AUTOSAR XML (schema 314)
package /ComponentType
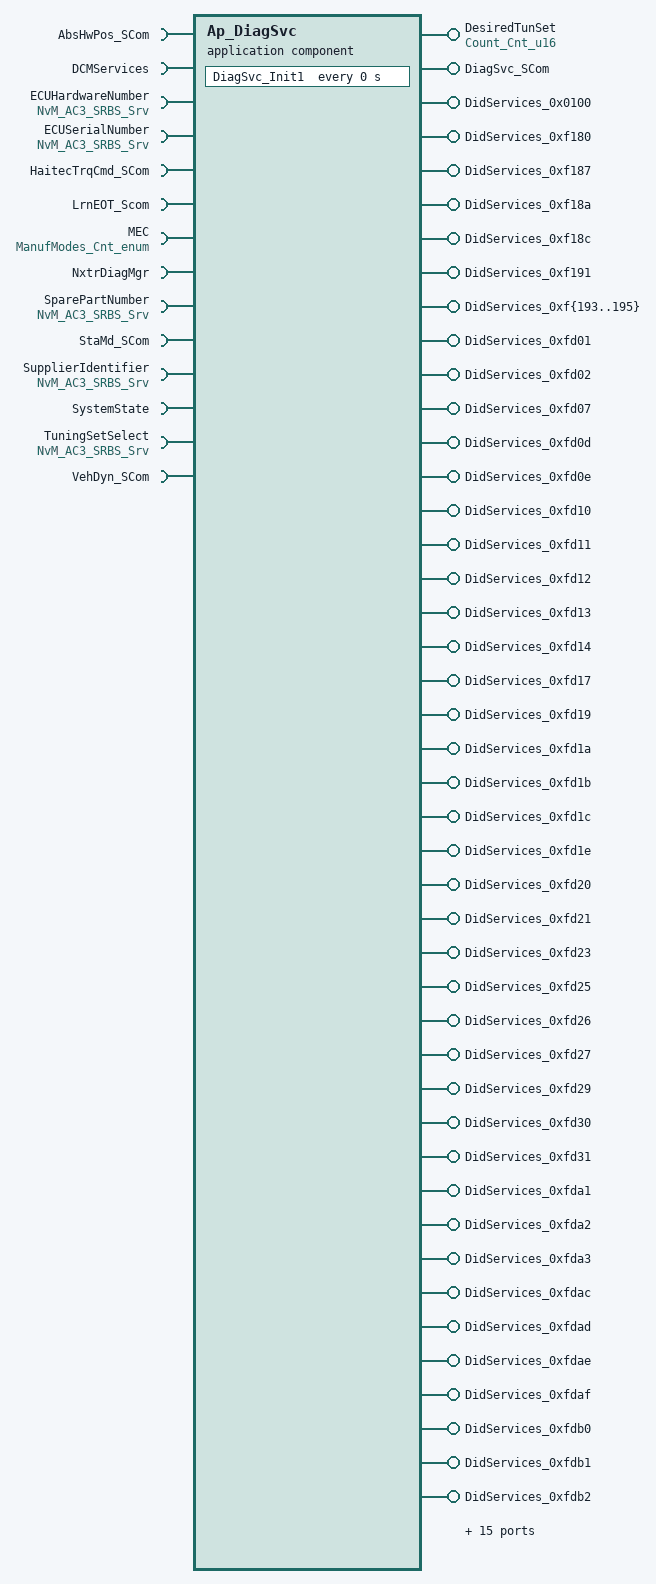
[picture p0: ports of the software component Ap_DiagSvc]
  application software component type Ap_DiagSvc
    63 x provide port:
      DesiredTunSet: unqueued-sender-com-spec{data-element=Cnt_u16, can-invalidate=false, init-value=D_ZERO_CNT_U16}, provided-interface=Count_Cnt_u16
      DiagSvc_SCom: provided-com-specs=[{operation=GetTuningSet, queue-length=1}, {operation=SetTuningSet, queue-length=1}], provided-interface=DiagSvc_SCom
      DidServices_0x0100: provided-interface=DidServices_0x0100
        provided-com-specs:
          operation=ConditionCheckRead, queue-length=1
          operation=ConditionCheckWrite, queue-length=1
          operation=ReadData, queue-length=1
          operation=WriteData, queue-length=1
      DidServices_0xf180: provided-com-specs=[{operation=ConditionCheckRead, queue-length=1}, {operation=ReadData, queue-length=1}], provided-interface=DidServices_0xf180
      DidServices_0xf187: provided-interface=DidServices_0xf187
        provided-com-specs:
          operation=ConditionCheckRead, queue-length=1
          operation=ConditionCheckWrite, queue-length=1
          operation=ReadData, queue-length=1
          operation=WriteData, queue-length=1
      DidServices_0xf18a: provided-interface=DidServices_0xf18a
        provided-com-specs:
          operation=ConditionCheckRead, queue-length=1
          operation=ConditionCheckWrite, queue-length=1
          operation=ReadData, queue-length=1
          operation=WriteData, queue-length=1
      DidServices_0xf18c: provided-com-specs=[{operation=ConditionCheckRead, queue-length=1}, {operation=ReadData, queue-length=1}], provided-interface=DidServices_0xf18c
      DidServices_0xf191: provided-com-specs=[{operation=ConditionCheckRead, queue-length=1}, {operation=ReadData, queue-length=1}], provided-interface=DidServices_0xf191
      DidServices_0xf{193..195}: provided-com-specs=[{operation=ConditionCheckRead, queue-length=1}, {operation=ReadData, queue-length=1}], provided-interface=DidServices_0xf{193..195}
      DidServices_0xfd01: provided-com-specs=[{operation=ConditionCheckRead, queue-length=1}, {operation=ReadData, queue-length=1}], provided-interface=DidServices_0xfd01
      DidServices_0xfd02: provided-interface=DidServices_0xfd02
        provided-com-specs:
          operation=ConditionCheckRead, queue-length=1
          operation=ConditionCheckWrite, queue-length=1
          operation=ReadData, queue-length=1
          operation=WriteData, queue-length=1
      DidServices_0xfd07: provided-interface=DidServices_0xfd07
        provided-com-specs:
          operation=ConditionCheckRead, queue-length=1
          operation=ConditionCheckWrite, queue-length=1
          operation=ReadData, queue-length=1
          operation=WriteData, queue-length=1
      DidServices_0xfd0d: provided-interface=DidServices_0xfd0d
        provided-com-specs:
          operation=ConditionCheckRead, queue-length=1
          operation=ReadData, queue-length=1
          operation=ReturnControlToECU, queue-length=1
          operation=ShortTermAdjustment, queue-length=1
      DidServices_0xfd0e: provided-com-specs=[{operation=ConditionCheckRead, queue-length=1}, {operation=ReadData, queue-length=1}], provided-interface=DidServices_0xfd0e
      DidServices_0xfd10: provided-com-specs=[{operation=ConditionCheckRead, queue-length=1}, {operation=ReadData, queue-length=1}], provided-interface=DidServices_0xfd10
      DidServices_0xfd11: provided-interface=DidServices_0xfd11
        provided-com-specs:
          operation=ConditionCheckRead, queue-length=1
          operation=ReadData, queue-length=1
          operation=ReturnControlToECU, queue-length=1
          operation=ShortTermAdjustment, queue-length=1
      DidServices_0xfd12: provided-interface=DidServices_0xfd12
        provided-com-specs:
          operation=ConditionCheckRead, queue-length=1
          operation=ConditionCheckWrite, queue-length=1
          operation=ReadData, queue-length=1
          operation=WriteData, queue-length=1
      DidServices_0xfd13: provided-com-specs=[{operation=ConditionCheckRead, queue-length=1}, {operation=ReadData, queue-length=1}], provided-interface=DidServices_0xfd13
      DidServices_0xfd14: provided-com-specs=[{operation=ConditionCheckRead, queue-length=1}, {operation=ReadData, queue-length=1}], provided-interface=DidServices_0xfd14
      DidServices_0xfd17: provided-com-specs=[{operation=ConditionCheckRead, queue-length=1}, {operation=ReadData, queue-length=1}], provided-interface=DidServices_0xfd17
      DidServices_0xfd19: provided-interface=DidServices_0xfd19
        provided-com-specs:
          operation=ConditionCheckRead, queue-length=1
          operation=ConditionCheckWrite, queue-length=1
          operation=ReadData, queue-length=1
          operation=WriteData, queue-length=1
      DidServices_0xfd1a: provided-com-specs=[{operation=ConditionCheckRead, queue-length=1}, {operation=ReadData, queue-length=1}], provided-interface=DidServices_0xfd1a
      DidServices_0xfd1b: provided-interface=DidServices_0xfd1b
        provided-com-specs:
          operation=ConditionCheckRead, queue-length=1
          operation=ConditionCheckWrite, queue-length=1
          operation=ReadData, queue-length=1
          operation=WriteData, queue-length=1
      DidServices_0xfd1c: provided-com-specs=[{operation=ConditionCheckRead, queue-length=1}, {operation=ReadData, queue-length=1}], provided-interface=DidServices_0xfd1c
      DidServices_0xfd1e: provided-interface=DidServices_0xfd1e
        provided-com-specs:
          operation=ConditionCheckRead, queue-length=1
          operation=ConditionCheckWrite, queue-length=1
          operation=ReadData, queue-length=1
          operation=WriteData, queue-length=1
      DidServices_0xfd20: provided-com-specs=[{operation=ConditionCheckRead, queue-length=1}, {operation=ReadData, queue-length=1}], provided-interface=DidServices_0xfd20
      DidServices_0xfd21: provided-interface=DidServices_0xfd21
        provided-com-specs:
          operation=ConditionCheckRead, queue-length=1
          operation=ConditionCheckWrite, queue-length=1
          operation=ReadData, queue-length=1
          operation=WriteData, queue-length=1
      DidServices_0xfd23: provided-interface=DidServices_0xfd23
        provided-com-specs:
          operation=ConditionCheckRead, queue-length=1
          operation=ConditionCheckWrite, queue-length=1
          operation=ReadData, queue-length=1
          operation=WriteData, queue-length=1
      DidServices_0xfd25: provided-interface=DidServices_0xfd25
        provided-com-specs:
          operation=ConditionCheckRead, queue-length=1
          operation=ConditionCheckWrite, queue-length=1
          operation=ReadData, queue-length=1
          operation=WriteData, queue-length=1
      DidServices_0xfd26: provided-interface=DidServices_0xfd26
        provided-com-specs:
          operation=ConditionCheckRead, queue-length=1
          operation=ConditionCheckWrite, queue-length=1
          operation=ReadData, queue-length=1
          operation=WriteData, queue-length=1
      DidServices_0xfd27: provided-interface=DidServices_0xfd27
        provided-com-specs:
          operation=ConditionCheckRead, queue-length=1
          operation=ConditionCheckWrite, queue-length=1
          operation=ReadData, queue-length=1
          operation=WriteData, queue-length=1
      DidServices_0xfd29: provided-interface=DidServices_0xfd29
        provided-com-specs:
          operation=ConditionCheckRead, queue-length=1
          operation=ConditionCheckWrite, queue-length=1
          operation=ReadData, queue-length=1
          operation=WriteData, queue-length=1
      DidServices_0xfd30: provided-interface=DidServices_0xfd30
        provided-com-specs:
          operation=ConditionCheckRead, queue-length=1
          operation=ConditionCheckWrite, queue-length=1
          operation=ReadData, queue-length=1
          operation=WriteData, queue-length=1
      DidServices_0xfd31: provided-com-specs=[{operation=ConditionCheckRead, queue-length=1}, {operation=ReadData, queue-length=1}], provided-interface=DidServices_0xfd31
      DidServices_0xfda1: provided-interface=DidServices_0xfda1
        provided-com-specs:
          operation=ConditionCheckRead, queue-length=1
          operation=ConditionCheckWrite, queue-length=1
          operation=ReadData, queue-length=1
          operation=WriteData, queue-length=1
      DidServices_0xfda2: provided-interface=DidServices_0xfda2
        provided-com-specs:
          operation=ConditionCheckRead, queue-length=1
          operation=ConditionCheckWrite, queue-length=1
          operation=ReadData, queue-length=1
          operation=WriteData, queue-length=1
      DidServices_0xfda3: provided-interface=DidServices_0xfda3
        provided-com-specs:
          operation=ConditionCheckRead, queue-length=1
          operation=ConditionCheckWrite, queue-length=1
          operation=ReadData, queue-length=1
          operation=WriteData, queue-length=1
      DidServices_0xfdac: provided-interface=DidServices_0xfdac
        provided-com-specs:
          operation=ConditionCheckRead, queue-length=1
          operation=ConditionCheckWrite, queue-length=1
          operation=ReadData, queue-length=1
          operation=WriteData, queue-length=1
      DidServices_0xfdad: provided-com-specs=[{operation=ConditionCheckRead, queue-length=1}, {operation=ReadData, queue-length=1}], provided-interface=DidServices_0xfdad
      DidServices_0xfdae: provided-interface=DidServices_0xfdae
        provided-com-specs:
          operation=ConditionCheckRead, queue-length=1
          operation=ConditionCheckWrite, queue-length=1
          operation=ReadData, queue-length=1
          operation=WriteData, queue-length=1
      DidServices_0xfdaf: provided-com-specs=[{operation=ConditionCheckRead, queue-length=1}, {operation=ReadData, queue-length=1}], provided-interface=DidServices_0xfdaf
      DidServices_0xfdb0: provided-interface=DidServices_0xfdb0
        provided-com-specs:
          operation=ConditionCheckRead, queue-length=1
          operation=ConditionCheckWrite, queue-length=1
          operation=ReadData, queue-length=1
          operation=WriteData, queue-length=1
      DidServices_0xfdb1: provided-interface=DidServices_0xfdb1
        provided-com-specs:
          operation=ConditionCheckRead, queue-length=1
          operation=ConditionCheckWrite, queue-length=1
          operation=ReadData, queue-length=1
          operation=WriteData, queue-length=1
      DidServices_0xfdb2: provided-interface=DidServices_0xfdb2
        provided-com-specs:
          operation=ConditionCheckRead, queue-length=1
          operation=ConditionCheckWrite, queue-length=1
          operation=ReadData, queue-length=1
          operation=WriteData, queue-length=1
      DidServices_0xfdb3: provided-interface=DidServices_0xfdb3
        provided-com-specs:
          operation=ConditionCheckRead, queue-length=1
          operation=ConditionCheckWrite, queue-length=1
          operation=ReadData, queue-length=1
          operation=WriteData, queue-length=1
      DidServices_0xfdb4: provided-interface=DidServices_0xfdb4
        provided-com-specs:
          operation=ConditionCheckRead, queue-length=1
          operation=ConditionCheckWrite, queue-length=1
          operation=ReadData, queue-length=1
          operation=WriteData, queue-length=1
      DidServices_0xfdb5: provided-interface=DidServices_0xfdb5
        provided-com-specs:
          operation=ConditionCheckRead, queue-length=1
          operation=ConditionCheckWrite, queue-length=1
          operation=ReadData, queue-length=1
          operation=WriteData, queue-length=1
      DidServices_0xfdb6: provided-interface=DidServices_0xfdb6
        provided-com-specs:
          operation=ConditionCheckRead, queue-length=1
          operation=ConditionCheckWrite, queue-length=1
          operation=ReadData, queue-length=1
          operation=WriteData, queue-length=1
      DidServices_0xfdb7: provided-interface=DidServices_0xfdb7
        provided-com-specs:
          operation=ConditionCheckRead, queue-length=1
          operation=ConditionCheckWrite, queue-length=1
          operation=ReadData, queue-length=1
          operation=WriteData, queue-length=1
      DidServices_0xfe00: provided-interface=DidServices_0xfe00
        provided-com-specs:
          operation=ConditionCheckRead, queue-length=1
          operation=ReadData, queue-length=1
          operation=ReturnControlToECU, queue-length=1
          operation=ShortTermAdjustment, queue-length=1
      RoutineServices_0xf000: server-com-spec{operation=Start, queue-length=1}, provided-interface=RoutineServices_0xf000
      RoutineServices_0xf001: server-com-spec{operation=Start, queue-length=1}, provided-interface=RoutineServices_0xf001
      RoutineServices_0xf{003..005}: server-com-spec{operation=Start, queue-length=1}, provided-interface=RoutineServices_0xf{003..005}
      RoutineServices_0xf008: server-com-spec{operation=Start, queue-length=1}, provided-interface=RoutineServices_0xf008
      RoutineServices_0xf009: provided-interface=RoutineServices_0xf009
        provided-com-specs:
          operation=RequestResults, queue-length=1
          operation=Start, queue-length=1
          operation=Stop, queue-length=1
      RoutineServices_0xf0ff: server-com-spec{operation=Start, queue-length=1}, provided-interface=RoutineServices_0xf0ff
      RoutineServices_0xfee0: server-com-spec{operation=Start, queue-length=1}, provided-interface=RoutineServices_0xfee0
      SecurityAccess_1: provided-com-specs=[{operation=CompareKey, queue-length=1}, {operation=GetSeed, queue-length=1}], provided-interface=SecurityAccess_1
      SessionControl: provided-interface=SessionControl
        provided-com-specs:
          operation=ChangeIndication, queue-length=1
          operation=ConfirmationRespPending, queue-length=1
          operation=GetSesChgPermission, queue-length=1
    14 x require port:
      AbsHwPos_SCom: required-com-specs=[CustClrTrim, CustSetTrim, NxtClearTrim, NxtSetTrim], required-interface=AbsHwPos_SCom
      DCMServices: required-com-specs=[GetSecurityLevel, GetSesCtrlType], required-interface=DCMServices
      ECUHardwareNumber: required-com-specs=[EraseBlock, GetErrorStatus, InvalidateNvBlock, ReadBlock, SetRamBlockStatus, WriteBlock], required-interface=NvM_AC3_SRBS_Srv
      ECUSerialNumber: required-com-specs=[EraseBlock, GetErrorStatus, InvalidateNvBlock, ReadBlock, SetRamBlockStatus, WriteBlock], required-interface=NvM_AC3_SRBS_Srv
      HaitecTrqCmd_SCom: required-com-specs=[StartCtrl, StopCtrl], required-interface=HaitecTrqCmd_SCom
      LrnEOT_Scom: client-com-spec=ResetEOT, required-interface=LrnEOT_Scom
      MEC: unqueued-receiver-com-spec{data-element=Cnt_enum, init-value=D_MANUFMODEINIT_CNT_ENUM}, required-interface=ManufModes_Cnt_enum
      NxtrDiagMgr: required-com-specs=[GetNTCActive, GetNTCFailed, GetNTCStatus, SetNTCStatus], required-interface=NxtrDiagMgr
      SparePartNumber: required-com-specs=[EraseBlock, GetErrorStatus, InvalidateNvBlock, ReadBlock, SetRamBlockStatus, WriteBlock], required-interface=NvM_AC3_SRBS_Srv
      StaMd_SCom: required-com-specs=[EcuReset, FBLTransitionReq], required-interface=StaMd_SCom
      SupplierIdentifier: required-com-specs=[EraseBlock, GetErrorStatus, InvalidateNvBlock, ReadBlock, SetRamBlockStatus, WriteBlock], required-interface=NvM_AC3_SRBS_Srv
      SystemState: required-interface=SystemState
      TuningSetSelect: required-com-specs=[EraseBlock, GetErrorStatus, InvalidateNvBlock, ReadBlock, SetRamBlockStatus, WriteBlock], required-interface=NvM_AC3_SRBS_Srv
      VehDyn_SCom: client-com-spec=ResetCenter, required-interface=VehDyn_SCom
  internal behavior Ap_DiagSvc_InternalBehavior: component=Ap_DiagSvc
    timing event DiagSvc_Init1_InitEvent: start-on-event=DiagSvc_Init1, period=0
    182 x operation invoked event:
      OIT_DiagSvc_SCom_GetTuningSet_DiagSvc_SCom_GetTuningSet: start-on-event=DiagSvc_SCom_GetTuningSet, operation=DiagSvc_SCom.GetTuningSet
      OIT_DiagSvc_SCom_SetTuningSet_DiagSvc_SCom_SetTuningSet: start-on-event=DiagSvc_SCom_SetTuningSet, operation=DiagSvc_SCom.SetTuningSet
      OIT_DidServices_0x0100_ReadData_DidServices_0x0100_ReadData: start-on-event=DidServices_0x0100_ReadData, operation=DidServices_0x0100.ReadData
      OIT_DidServices_0x0100_WriteData_DidServices_0x0100_WriteData: start-on-event=DidServices_0x0100_WriteData, operation=DidServices_0x0100.WriteData
      OIT_DidServices_0xf180_ReadData_DidServices_0xf180_ReadData: start-on-event=DidServices_0xf180_ReadData, operation=DidServices_0xf180.ReadData
      OIT_DidServices_0xf187_ReadData_DidServices_0xf187_ReadData: start-on-event=DidServices_0xf187_ReadData, operation=DidServices_0xf187.ReadData
      OIT_DidServices_0xf187_WriteData_DidServices_0xf187_WriteData: start-on-event=DidServices_0xf187_WriteData, operation=DidServices_0xf187.WriteData
      OIT_DidServices_0xf18a_ReadData_DidServices_0xf18a_ReadData: start-on-event=DidServices_0xf18a_ReadData, operation=DidServices_0xf18a.ReadData
      OIT_DidServices_0xf18a_WriteData_DidServices_0xf18a_WriteData: start-on-event=DidServices_0xf18a_WriteData, operation=DidServices_0xf18a.WriteData
      OIT_DidServices_0xf18c_ReadData_DidServices_0xf18c_ReadData: start-on-event=DidServices_0xf18c_ReadData, operation=DidServices_0xf18c.ReadData
      OIT_DidServices_0xf191_ReadData_DidServices_0xf191_ReadData: start-on-event=DidServices_0xf191_ReadData, operation=DidServices_0xf191.ReadData
      OIT_DidServices_0xf{193..195}_ReadData_DidServices_0xf{193..195}_ReadData: start-on-event=DidServices_0xf{193..195}_ReadData, operation=DidServices_0xf{193..195}.ReadData
      OIT_DidServices_0xfd01_ReadData_DidServices_0xfd01_ReadData: start-on-event=DidServices_0xfd01_ReadData, operation=DidServices_0xfd01.ReadData
      OIT_DidServices_0xfd02_ReadData_DidServices_0xfd02_ReadData: start-on-event=DidServices_0xfd02_ReadData, operation=DidServices_0xfd02.ReadData
      OIT_DidServices_0xfd02_WriteData_DidServices_0xfd02_WriteData: start-on-event=DidServices_0xfd02_WriteData, operation=DidServices_0xfd02.WriteData
      OIT_DidServices_0xfd07_ReadData_DidServices_0xfd07_ReadData: start-on-event=DidServices_0xfd07_ReadData, operation=DidServices_0xfd07.ReadData
      OIT_DidServices_0xfd07_WriteData_DidServices_0xfd07_WriteData: start-on-event=DidServices_0xfd07_WriteData, operation=DidServices_0xfd07.WriteData
      OIT_DidServices_0xfd0d_ReadData_DidServices_0xfd0d_ReadData: start-on-event=DidServices_0xfd0d_ReadData, operation=DidServices_0xfd0d.ReadData
      OIT_DidServices_0xfd0d_ReturnControlToECU_DidServices_0xfd0d_ReturnControlToECU: start-on-event=DidServices_0xfd0d_ReturnControlToECU, operation=DidServices_0xfd0d.ReturnControlToECU
      OIT_DidServices_0xfd0d_ShortTermAdjustment_DidServices_0xfd0d_ShortTermAdjustment: start-on-event=DidServices_0xfd0d_ShortTermAdjustment, operation=DidServices_0xfd0d.ShortTermAdjustment
      OIT_DidServices_0xfd0e_ReadData_DidServices_0xfd0e_ReadData: start-on-event=DidServices_0xfd0e_ReadData, operation=DidServices_0xfd0e.ReadData
      OIT_DidServices_0xfd10_ReadData_DidServices_0xfd10_ReadData: start-on-event=DidServices_0xfd10_ReadData, operation=DidServices_0xfd10.ReadData
      OIT_DidServices_0xfd11_ReadData_DidServices_0xfd11_ReadData: start-on-event=DidServices_0xfd11_ReadData, operation=DidServices_0xfd11.ReadData
      OIT_DidServices_0xfd11_ReturnControlToECU_DidServices_0xfd11_ReturnControlToECU: start-on-event=DidServices_0xfd11_ReturnControlToECU, operation=DidServices_0xfd11.ReturnControlToECU
      OIT_DidServices_0xfd11_ShortTermAdjustment_DidServices_0xfd11_ShortTermAdjustment: start-on-event=DidServices_0xfd11_ShortTermAdjustment, operation=DidServices_0xfd11.ShortTermAdjustment
      OIT_DidServices_0xfd12_ReadData_DidServices_0xfd12_ReadData: start-on-event=DidServices_0xfd12_ReadData, operation=DidServices_0xfd12.ReadData
      OIT_DidServices_0xfd12_WriteData_DidServices_0xfd12_WriteData: start-on-event=DidServices_0xfd12_WriteData, operation=DidServices_0xfd12.WriteData
      OIT_DidServices_0xfd13_ReadData_DidServices_0xfd13_ReadData: start-on-event=DidServices_0xfd13_ReadData, operation=DidServices_0xfd13.ReadData
      OIT_DidServices_0xfd14_ReadData_DidServices_0xfd14_ReadData: start-on-event=DidServices_0xfd14_ReadData, operation=DidServices_0xfd14.ReadData
      OIT_DidServices_0xfd17_ReadData_DidServices_0xfd17_ReadData: start-on-event=DidServices_0xfd17_ReadData, operation=DidServices_0xfd17.ReadData
      OIT_DidServices_0xfd19_ReadData_DidServices_0xfd19_ReadData: start-on-event=DidServices_0xfd19_ReadData, operation=DidServices_0xfd19.ReadData
      OIT_DidServices_0xfd19_WriteData_DidServices_0xfd19_WriteData: start-on-event=DidServices_0xfd19_WriteData, operation=DidServices_0xfd19.WriteData
      OIT_DidServices_0xfd1a_ReadData_DidServices_0xfd1a_ReadData: start-on-event=DidServices_0xfd1a_ReadData, operation=DidServices_0xfd1a.ReadData
      OIT_DidServices_0xfd1b_ReadData_DidServices_0xfd1b_ReadData: start-on-event=DidServices_0xfd1b_ReadData, operation=DidServices_0xfd1b.ReadData
      OIT_DidServices_0xfd1b_WriteData_DidServices_0xfd1b_WriteData: start-on-event=DidServices_0xfd1b_WriteData, operation=DidServices_0xfd1b.WriteData
      OIT_DidServices_0xfd1c_ReadData_DidServices_0xfd1c_ReadData: start-on-event=DidServices_0xfd1c_ReadData, operation=DidServices_0xfd1c.ReadData
      OIT_DidServices_0xfd1e_ReadData_DidServices_0xfd1e_ReadData: start-on-event=DidServices_0xfd1e_ReadData, operation=DidServices_0xfd1e.ReadData
      OIT_DidServices_0xfd1e_WriteData_DidServices_0xfd1e_WriteData: start-on-event=DidServices_0xfd1e_WriteData, operation=DidServices_0xfd1e.WriteData
      OIT_DidServices_0xfd20_ReadData_DidServices_0xfd20_ReadData: start-on-event=DidServices_0xfd20_ReadData, operation=DidServices_0xfd20.ReadData
      OIT_DidServices_0xfd21_ReadData_DidServices_0xfd21_ReadData: start-on-event=DidServices_0xfd21_ReadData, operation=DidServices_0xfd21.ReadData
      OIT_DidServices_0xfd21_WriteData_DidServices_0xfd21_WriteData: start-on-event=DidServices_0xfd21_WriteData, operation=DidServices_0xfd21.WriteData
      OIT_DidServices_0xfd23_ReadData_DidServices_0xfd23_ReadData: start-on-event=DidServices_0xfd23_ReadData, operation=DidServices_0xfd23.ReadData
      OIT_DidServices_0xfd23_WriteData_DidServices_0xfd23_WriteData: start-on-event=DidServices_0xfd23_WriteData, operation=DidServices_0xfd23.WriteData
      OIT_DidServices_0xfd25_ReadData_DidServices_0xfd25_ReadData: start-on-event=DidServices_0xfd25_ReadData, operation=DidServices_0xfd25.ReadData
      OIT_DidServices_0xfd25_WriteData_DidServices_0xfd25_WriteData: start-on-event=DidServices_0xfd25_WriteData, operation=DidServices_0xfd25.WriteData
      OIT_DidServices_0xfd26_ReadData_DidServices_0xfd26_ReadData: start-on-event=DidServices_0xfd26_ReadData, operation=DidServices_0xfd26.ReadData
      OIT_DidServices_0xfd26_WriteData_DidServices_0xfd26_WriteData: start-on-event=DidServices_0xfd26_WriteData, operation=DidServices_0xfd26.WriteData
      OIT_DidServices_0xfd27_ReadData_DidServices_0xfd27_ReadData: start-on-event=DidServices_0xfd27_ReadData, operation=DidServices_0xfd27.ReadData
      OIT_DidServices_0xfd27_WriteData_DidServices_0xfd27_WriteData: start-on-event=DidServices_0xfd27_WriteData, operation=DidServices_0xfd27.WriteData
      OIT_DidServices_0xfd29_ReadData_DidServices_0xfd29_ReadData: start-on-event=DidServices_0xfd29_ReadData, operation=DidServices_0xfd29.ReadData
      OIT_DidServices_0xfd29_WriteData_DidServices_0xfd29_WriteData: start-on-event=DidServices_0xfd29_WriteData, operation=DidServices_0xfd29.WriteData
      OIT_DidServices_0xfd30_ReadData_DidServices_0xfd30_ReadData: start-on-event=DidServices_0xfd30_ReadData, operation=DidServices_0xfd30.ReadData
      OIT_DidServices_0xfd30_WriteData_DidServices_0xfd30_WriteData: start-on-event=DidServices_0xfd30_WriteData, operation=DidServices_0xfd30.WriteData
      OIT_DidServices_0xfd31_ReadData_DidServices_0xfd31_ReadData: start-on-event=DidServices_0xfd31_ReadData, operation=DidServices_0xfd31.ReadData
      OIT_DidServices_0xfda1_ReadData_DidServices_0xfda1_ReadData: start-on-event=DidServices_0xfda1_ReadData, operation=DidServices_0xfda1.ReadData
      OIT_DidServices_0xfda1_WriteData_DidServices_0xfda1_WriteData: start-on-event=DidServices_0xfda1_WriteData, operation=DidServices_0xfda1.WriteData
      OIT_DidServices_0xfda2_ReadData_DidServices_0xfda2_ReadData: start-on-event=DidServices_0xfda2_ReadData, operation=DidServices_0xfda2.ReadData
      OIT_DidServices_0xfda2_WriteData_DidServices_0xfda2_WriteData: start-on-event=DidServices_0xfda2_WriteData, operation=DidServices_0xfda2.WriteData
      OIT_DidServices_0xfda3_ReadData_DidServices_0xfda3_ReadData: start-on-event=DidServices_0xfda3_ReadData, operation=DidServices_0xfda3.ReadData
      OIT_DidServices_0xfda3_WriteData_DidServices_0xfda3_WriteData: start-on-event=DidServices_0xfda3_WriteData, operation=DidServices_0xfda3.WriteData
      OIT_DidServices_0xfdac_ReadData_DidServices_0xfdac_ReadData: start-on-event=DidServices_0xfdac_ReadData, operation=DidServices_0xfdac.ReadData
      OIT_DidServices_0xfdac_WriteData_DidServices_0xfdac_WriteData: start-on-event=DidServices_0xfdac_WriteData, operation=DidServices_0xfdac.WriteData
      OIT_DidServices_0xfdad_ReadData_DidServices_0xfdad_ReadData: start-on-event=DidServices_0xfdad_ReadData, operation=DidServices_0xfdad.ReadData
      OIT_DidServices_0xfdae_ReadData_DidServices_0xfdae_ReadData: start-on-event=DidServices_0xfdae_ReadData, operation=DidServices_0xfdae.ReadData
      OIT_DidServices_0xfdae_WriteData_DidServices_0xfdae_WriteData: start-on-event=DidServices_0xfdae_WriteData, operation=DidServices_0xfdae.WriteData
      OIT_DidServices_0xfdaf_ReadData_DidServices_0xfdaf_ReadData: start-on-event=DidServices_0xfdaf_ReadData, operation=DidServices_0xfdaf.ReadData
      OIT_DidServices_0xfdb0_ReadData_DidServices_0xfdb0_ReadData: start-on-event=DidServices_0xfdb0_ReadData, operation=DidServices_0xfdb0.ReadData
      OIT_DidServices_0xfdb0_WriteData_DidServices_0xfdb0_WriteData: start-on-event=DidServices_0xfdb0_WriteData, operation=DidServices_0xfdb0.WriteData
      OIT_DidServices_0xfdb1_ReadData_DidServices_0xfdb1_ReadData: start-on-event=DidServices_0xfdb1_ReadData, operation=DidServices_0xfdb1.ReadData
      OIT_DidServices_0xfdb1_WriteData_DidServices_0xfdb1_WriteData: start-on-event=DidServices_0xfdb1_WriteData, operation=DidServices_0xfdb1.WriteData
      OIT_DidServices_0xfdb2_ReadData_DidServices_0xfdb2_ReadData: start-on-event=DidServices_0xfdb2_ReadData, operation=DidServices_0xfdb2.ReadData
      OIT_DidServices_0xfdb2_WriteData_DidServices_0xfdb2_WriteData: start-on-event=DidServices_0xfdb2_WriteData, operation=DidServices_0xfdb2.WriteData
      OIT_DidServices_0xfdb3_ReadData_DidServices_0xfdb3_ReadData: start-on-event=DidServices_0xfdb3_ReadData, operation=DidServices_0xfdb3.ReadData
      OIT_DidServices_0xfdb3_WriteData_DidServices_0xfdb3_WriteData: start-on-event=DidServices_0xfdb3_WriteData, operation=DidServices_0xfdb3.WriteData
      OIT_DidServices_0xfdb4_ReadData_DidServices_0xfdb4_ReadData: start-on-event=DidServices_0xfdb4_ReadData, operation=DidServices_0xfdb4.ReadData
      OIT_DidServices_0xfdb4_WriteData_DidServices_0xfdb4_WriteData: start-on-event=DidServices_0xfdb4_WriteData, operation=DidServices_0xfdb4.WriteData
      OIT_DidServices_0xfdb5_ReadData_DidServices_0xfdb5_ReadData: start-on-event=DidServices_0xfdb5_ReadData, operation=DidServices_0xfdb5.ReadData
      OIT_DidServices_0xfdb5_WriteData_DidServices_0xfdb5_WriteData: start-on-event=DidServices_0xfdb5_WriteData, operation=DidServices_0xfdb5.WriteData
      OIT_DidServices_0xfdb6_ReadData_DidServices_0xfdb6_ReadData: start-on-event=DidServices_0xfdb6_ReadData, operation=DidServices_0xfdb6.ReadData
      OIT_DidServices_0xfdb6_WriteData_DidServices_0xfdb6_WriteData: start-on-event=DidServices_0xfdb6_WriteData, operation=DidServices_0xfdb6.WriteData
      OIT_DidServices_0xfdb7_ReadData_DidServices_0xfdb7_ReadData: start-on-event=DidServices_0xfdb7_ReadData, operation=DidServices_0xfdb7.ReadData
      OIT_DidServices_0xfdb7_WriteData_DidServices_0xfdb7_WriteData: start-on-event=DidServices_0xfdb7_WriteData, operation=DidServices_0xfdb7.WriteData
      OIT_DidServices_0xfe00_ReadData_DidServices_0xfe00_ReadData: start-on-event=DidServices_0xfe00_ReadData, operation=DidServices_0xfe00.ReadData
      OIT_DidServices_0xfe00_ReturnControlToECU_DidServices_0xfe00_ReturnControlToECU: start-on-event=DidServices_0xfe00_ReturnControlToECU, operation=DidServices_0xfe00.ReturnControlToECU
      OIT_DidServices_0xfe00_ShortTermAdjustment_DidServices_0xfe00_ShortTermAdjustment: start-on-event=DidServices_0xfe00_ShortTermAdjustment, operation=DidServices_0xfe00.ShortTermAdjustment
      OIT_DidServices_Customer_ConditionCheckRead_DidServices_0x0100_ConditionCheckRead: start-on-event=DidServices_Customer_ConditionCheckRead, operation=DidServices_0x0100.ConditionCheckRead
      OIT_DidServices_Customer_ConditionCheckRead_DidServices_0xf180_ConditionCheckRead: start-on-event=DidServices_Customer_ConditionCheckRead, operation=DidServices_0xf180.ConditionCheckRead
      OIT_DidServices_Customer_ConditionCheckRead_DidServices_0xf187_ConditionCheckRead: start-on-event=DidServices_Customer_ConditionCheckRead, operation=DidServices_0xf187.ConditionCheckRead
      OIT_DidServices_Customer_ConditionCheckRead_DidServices_0xf18a_ConditionCheckRead: start-on-event=DidServices_Customer_ConditionCheckRead, operation=DidServices_0xf18a.ConditionCheckRead
      OIT_DidServices_Customer_ConditionCheckRead_DidServices_0xf18c_ConditionCheckRead: start-on-event=DidServices_Customer_ConditionCheckRead, operation=DidServices_0xf18c.ConditionCheckRead
      OIT_DidServices_Customer_ConditionCheckRead_DidServices_0xf191_ConditionCheckRead: start-on-event=DidServices_Customer_ConditionCheckRead, operation=DidServices_0xf191.ConditionCheckRead
      OIT_DidServices_Customer_ConditionCheckRead_DidServices_0xf{193..195}_ConditionCheckRead: start-on-event=DidServices_Customer_ConditionCheckRead, operation=DidServices_0xf{193..195}.ConditionCheckRead
      OIT_DidServices_Customer_ConditionCheckWrite_DidServices_0x0100_ConditionCheckWrite: start-on-event=DidServices_Customer_ConditionCheckWrite, operation=DidServices_0x0100.ConditionCheckWrite
      OIT_DidServices_Customer_ConditionCheckWrite_DidServices_0xf187_ConditionCheckWrite: start-on-event=DidServices_Customer_ConditionCheckWrite, operation=DidServices_0xf187.ConditionCheckWrite
      OIT_DidServices_Customer_ConditionCheckWrite_DidServices_0xf18a_ConditionCheckWrite: start-on-event=DidServices_Customer_ConditionCheckWrite, operation=DidServices_0xf18a.ConditionCheckWrite
      OIT_DidServices_Nexteer_ConditionCheckRead_DidServices_0xfd01_ConditionCheckRead: start-on-event=DidServices_Nexteer_ConditionCheckRead, operation=DidServices_0xfd01.ConditionCheckRead
      OIT_DidServices_Nexteer_ConditionCheckRead_DidServices_0xfd02_ConditionCheckRead: start-on-event=DidServices_Nexteer_ConditionCheckRead, operation=DidServices_0xfd02.ConditionCheckRead
      OIT_DidServices_Nexteer_ConditionCheckRead_DidServices_0xfd07_ConditionCheckRead: start-on-event=DidServices_Nexteer_ConditionCheckRead, operation=DidServices_0xfd07.ConditionCheckRead
      OIT_DidServices_Nexteer_ConditionCheckRead_DidServices_0xfd0e_ConditionCheckRead: start-on-event=DidServices_Nexteer_ConditionCheckRead, operation=DidServices_0xfd0e.ConditionCheckRead
      OIT_DidServices_Nexteer_ConditionCheckRead_DidServices_0xfd10_ConditionCheckRead: start-on-event=DidServices_Nexteer_ConditionCheckRead, operation=DidServices_0xfd10.ConditionCheckRead
      OIT_DidServices_Nexteer_ConditionCheckRead_DidServices_0xfd{12..14}_ConditionCheckRead: start-on-event=DidServices_Nexteer_ConditionCheckRead, operation=DidServices_0xfd{12..14}.ConditionCheckRead
      OIT_DidServices_Nexteer_ConditionCheckRead_DidServices_0xfd17_ConditionCheckRead: start-on-event=DidServices_Nexteer_ConditionCheckRead, operation=DidServices_0xfd17.ConditionCheckRead
      OIT_DidServices_Nexteer_ConditionCheckRead_DidServices_0xfd19_ConditionCheckRead: start-on-event=DidServices_Nexteer_ConditionCheckRead, operation=DidServices_0xfd19.ConditionCheckRead
      OIT_DidServices_Nexteer_ConditionCheckRead_DidServices_0xfd1a_ConditionCheckRead: start-on-event=DidServices_Nexteer_ConditionCheckRead, operation=DidServices_0xfd1a.ConditionCheckRead
      OIT_DidServices_Nexteer_ConditionCheckRead_DidServices_0xfd1b_ConditionCheckRead: start-on-event=DidServices_Nexteer_ConditionCheckRead, operation=DidServices_0xfd1b.ConditionCheckRead
      OIT_DidServices_Nexteer_ConditionCheckRead_DidServices_0xfd1c_ConditionCheckRead: start-on-event=DidServices_Nexteer_ConditionCheckRead, operation=DidServices_0xfd1c.ConditionCheckRead
      OIT_DidServices_Nexteer_ConditionCheckRead_DidServices_0xfd1e_ConditionCheckRead: start-on-event=DidServices_Nexteer_ConditionCheckRead, operation=DidServices_0xfd1e.ConditionCheckRead
      OIT_DidServices_Nexteer_ConditionCheckRead_DidServices_0xfd20_ConditionCheckRead: start-on-event=DidServices_Nexteer_ConditionCheckRead, operation=DidServices_0xfd20.ConditionCheckRead
      OIT_DidServices_Nexteer_ConditionCheckRead_DidServices_0xfd21_ConditionCheckRead: start-on-event=DidServices_Nexteer_ConditionCheckRead, operation=DidServices_0xfd21.ConditionCheckRead
      OIT_DidServices_Nexteer_ConditionCheckRead_DidServices_0xfd23_ConditionCheckRead: start-on-event=DidServices_Nexteer_ConditionCheckRead, operation=DidServices_0xfd23.ConditionCheckRead
      OIT_DidServices_Nexteer_ConditionCheckRead_DidServices_0xfd{25..27}_ConditionCheckRead: start-on-event=DidServices_Nexteer_ConditionCheckRead, operation=DidServices_0xfd{25..27}.ConditionCheckRead
      OIT_DidServices_Nexteer_ConditionCheckRead_DidServices_0xfd{29..31}_ConditionCheckRead: start-on-event=DidServices_Nexteer_ConditionCheckRead, operation=DidServices_0xfd{29..31}.ConditionCheckRead
      OIT_DidServices_Nexteer_ConditionCheckRead_DidServices_0xfda{1..3}_ConditionCheckRead: start-on-event=DidServices_Nexteer_ConditionCheckRead, operation=DidServices_0xfda{1..3}.ConditionCheckRead
      OIT_DidServices_Nexteer_ConditionCheckRead_DidServices_0xfdac_ConditionCheckRead: start-on-event=DidServices_Nexteer_ConditionCheckRead, operation=DidServices_0xfdac.ConditionCheckRead
      OIT_DidServices_Nexteer_ConditionCheckRead_DidServices_0xfdad_ConditionCheckRead: start-on-event=DidServices_Nexteer_ConditionCheckRead, operation=DidServices_0xfdad.ConditionCheckRead
      OIT_DidServices_Nexteer_ConditionCheckRead_DidServices_0xfdae_ConditionCheckRead: start-on-event=DidServices_Nexteer_ConditionCheckRead, operation=DidServices_0xfdae.ConditionCheckRead
      OIT_DidServices_Nexteer_ConditionCheckRead_DidServices_0xfdaf_ConditionCheckRead: start-on-event=DidServices_Nexteer_ConditionCheckRead, operation=DidServices_0xfdaf.ConditionCheckRead
      OIT_DidServices_Nexteer_ConditionCheckRead_DidServices_0xfdb{0..7}_ConditionCheckRead: start-on-event=DidServices_Nexteer_ConditionCheckRead, operation=DidServices_0xfdb{0..7}.ConditionCheckRead
      OIT_DidServices_Nexteer_ConditionCheckWrite_DidServices_0xfd02_ConditionCheckWrite: start-on-event=DidServices_Nexteer_ConditionCheckWrite, operation=DidServices_0xfd02.ConditionCheckWrite
      OIT_DidServices_Nexteer_ConditionCheckWrite_DidServices_0xfd07_ConditionCheckWrite: start-on-event=DidServices_Nexteer_ConditionCheckWrite, operation=DidServices_0xfd07.ConditionCheckWrite
      OIT_DidServices_Nexteer_ConditionCheckWrite_DidServices_0xfd12_ConditionCheckWrite: start-on-event=DidServices_Nexteer_ConditionCheckWrite, operation=DidServices_0xfd12.ConditionCheckWrite
      OIT_DidServices_Nexteer_ConditionCheckWrite_DidServices_0xfd19_ConditionCheckWrite: start-on-event=DidServices_Nexteer_ConditionCheckWrite, operation=DidServices_0xfd19.ConditionCheckWrite
      OIT_DidServices_Nexteer_ConditionCheckWrite_DidServices_0xfd1b_ConditionCheckWrite: start-on-event=DidServices_Nexteer_ConditionCheckWrite, operation=DidServices_0xfd1b.ConditionCheckWrite
      OIT_DidServices_Nexteer_ConditionCheckWrite_DidServices_0xfd1e_ConditionCheckWrite: start-on-event=DidServices_Nexteer_ConditionCheckWrite, operation=DidServices_0xfd1e.ConditionCheckWrite
      OIT_DidServices_Nexteer_ConditionCheckWrite_DidServices_0xfd21_ConditionCheckWrite: start-on-event=DidServices_Nexteer_ConditionCheckWrite, operation=DidServices_0xfd21.ConditionCheckWrite
      OIT_DidServices_Nexteer_ConditionCheckWrite_DidServices_0xfd23_ConditionCheckWrite: start-on-event=DidServices_Nexteer_ConditionCheckWrite, operation=DidServices_0xfd23.ConditionCheckWrite
      OIT_DidServices_Nexteer_ConditionCheckWrite_DidServices_0xfd{25..27}_ConditionCheckWrite: start-on-event=DidServices_Nexteer_ConditionCheckWrite, operation=DidServices_0xfd{25..27}.ConditionCheckWrite
      OIT_DidServices_Nexteer_ConditionCheckWrite_DidServices_0xfd29_ConditionCheckWrite: start-on-event=DidServices_Nexteer_ConditionCheckWrite, operation=DidServices_0xfd29.ConditionCheckWrite
      OIT_DidServices_Nexteer_ConditionCheckWrite_DidServices_0xfd30_ConditionCheckWrite: start-on-event=DidServices_Nexteer_ConditionCheckWrite, operation=DidServices_0xfd30.ConditionCheckWrite
      OIT_DidServices_Nexteer_ConditionCheckWrite_DidServices_0xfda{1..3}_ConditionCheckWrite: start-on-event=DidServices_Nexteer_ConditionCheckWrite, operation=DidServices_0xfda{1..3}.ConditionCheckWrite
      OIT_DidServices_Nexteer_ConditionCheckWrite_DidServices_0xfdac_ConditionCheckWrite: start-on-event=DidServices_Nexteer_ConditionCheckWrite, operation=DidServices_0xfdac.ConditionCheckWrite
      OIT_DidServices_Nexteer_ConditionCheckWrite_DidServices_0xfdae_ConditionCheckWrite: start-on-event=DidServices_Nexteer_ConditionCheckWrite, operation=DidServices_0xfdae.ConditionCheckWrite
      OIT_DidServices_Nexteer_ConditionCheckWrite_DidServices_0xfdb{0..7}_ConditionCheckWrite: start-on-event=DidServices_Nexteer_ConditionCheckWrite, operation=DidServices_0xfdb{0..7}.ConditionCheckWrite
      OIT_DidServices_Service2F_ConditionCheckRead_DidServices_0xfd0d_ConditionCheckRead: start-on-event=DidServices_Service2F_ConditionCheckRead, operation=DidServices_0xfd0d.ConditionCheckRead
      OIT_DidServices_Service2F_ConditionCheckRead_DidServices_0xfd11_ConditionCheckRead: start-on-event=DidServices_Service2F_ConditionCheckRead, operation=DidServices_0xfd11.ConditionCheckRead
      OIT_DidServices_Service2F_ConditionCheckRead_DidServices_0xfe00_ConditionCheckRead: start-on-event=DidServices_Service2F_ConditionCheckRead, operation=DidServices_0xfe00.ConditionCheckRead
      OIT_RoutineServices_0xf000_Start_RoutineServices_0xf000_Start: start-on-event=RoutineServices_0xf000_Start, operation=RoutineServices_0xf000.Start
      OIT_RoutineServices_0xf001_Start_RoutineServices_0xf001_Start: start-on-event=RoutineServices_0xf001_Start, operation=RoutineServices_0xf001.Start
      OIT_RoutineServices_0xf{003..005}_Start_RoutineServices_0xf{003..005}_Start: start-on-event=RoutineServices_0xf{003..005}_Start, operation=RoutineServices_0xf{003..005}.Start
      OIT_RoutineServices_0xf008_Start_RoutineServices_0xf008_Start: start-on-event=RoutineServices_0xf008_Start, operation=RoutineServices_0xf008.Start
      OIT_RoutineServices_0xf009_RequestResults_RoutineServices_0xf009_RequestResults: start-on-event=RoutineServices_0xf009_RequestResults, operation=RoutineServices_0xf009.RequestResults
      OIT_RoutineServices_0xf009_Start_RoutineServices_0xf009_Start: start-on-event=RoutineServices_0xf009_Start, operation=RoutineServices_0xf009.Start
      OIT_RoutineServices_0xf009_Stop_RoutineServices_0xf009_Stop: start-on-event=RoutineServices_0xf009_Stop, operation=RoutineServices_0xf009.Stop
      OIT_RoutineServices_0xf0ff_Start_RoutineServices_0xf0ff_Start: start-on-event=RoutineServices_0xf0ff_Start, operation=RoutineServices_0xf0ff.Start
      OIT_RoutineServices_0xfee0_Start_RoutineServices_0xfee0_Start: start-on-event=RoutineServices_0xfee0_Start, operation=RoutineServices_0xfee0.Start
      OIT_SecurityAccess_1_CompareKey_SecurityAccess_1_CompareKey: start-on-event=SecurityAccess_1_CompareKey, operation=SecurityAccess_1.CompareKey
      OIT_SecurityAccess_1_GetSeed_SecurityAccess_1_GetSeed: start-on-event=SecurityAccess_1_GetSeed, operation=SecurityAccess_1.GetSeed
      OIT_SessionControl_ChangeIndication_SessionControl_ChangeIndication: start-on-event=SessionControl_ChangeIndication, operation=SessionControl.ChangeIndication
      OIT_SessionControl_ConfirmationRespPending_SessionControl_ConfirmationRespPending: start-on-event=SessionControl_ConfirmationRespPending, operation=SessionControl.ConfirmationRespPending
      OIT_SessionControl_GetSesChgPermission_SessionControl_GetSesChgPermission: start-on-event=SessionControl_GetSesChgPermission, operation=SessionControl.GetSesChgPermission
    per instance memory SparePartNumberData: type=Dcm_10Byte_Type, type-definition=/DataType/Dcm_10Byte_Type
    per instance memory SupplierIdentifierData: type=Dcm_10Byte_Type, type-definition=/DataType/Dcm_10Byte_Type
    per instance memory TuningSetSelectData: type=UInt16, type-definition=/DataType/UInt16
    port-api-options:
      enable-take-address=false, indirect-api=false, port=AbsHwPos_SCom
      enable-take-address=false, indirect-api=false, port=DCMServices
      enable-take-address=false, indirect-api=false, port=DesiredTunSet
      enable-take-address=false, indirect-api=false, port=DiagSvc_SCom
      enable-take-address=false, indirect-api=false, port=DidServices_0x0100
      enable-take-address=false, indirect-api=false, port=DidServices_0xf180
      enable-take-address=false, indirect-api=false, port=DidServices_0xf187
      enable-take-address=false, indirect-api=false, port=DidServices_0xf18a
      enable-take-address=false, indirect-api=false, port=DidServices_0xf18c
      enable-take-address=false, indirect-api=false, port=DidServices_0xf191
      enable-take-address=false, indirect-api=false, port=DidServices_0xf{193..195}
      enable-take-address=false, indirect-api=false, port=DidServices_0xfd01
      enable-take-address=false, indirect-api=false, port=DidServices_0xfd02
      enable-take-address=false, indirect-api=false, port=DidServices_0xfd07
      enable-take-address=false, indirect-api=false, port=DidServices_0xfd0d
      enable-take-address=false, indirect-api=false, port=DidServices_0xfd0e
      enable-take-address=false, indirect-api=false, port=DidServices_0xfd{10..14}
      enable-take-address=false, indirect-api=false, port=DidServices_0xfd17
      enable-take-address=false, indirect-api=false, port=DidServices_0xfd19
      enable-take-address=false, indirect-api=false, port=DidServices_0xfd1a
      enable-take-address=false, indirect-api=false, port=DidServices_0xfd1b
      enable-take-address=false, indirect-api=false, port=DidServices_0xfd1c
      enable-take-address=false, indirect-api=false, port=DidServices_0xfd1e
      enable-take-address=false, indirect-api=false, port=DidServices_0xfd20
      enable-take-address=false, indirect-api=false, port=DidServices_0xfd21
      enable-take-address=false, indirect-api=false, port=DidServices_0xfd23
      enable-take-address=false, indirect-api=false, port=DidServices_0xfd{25..27}
      enable-take-address=false, indirect-api=false, port=DidServices_0xfd{29..31}
      enable-take-address=false, indirect-api=false, port=DidServices_0xfda{1..3}
      enable-take-address=false, indirect-api=false, port=DidServices_0xfdac
      enable-take-address=false, indirect-api=false, port=DidServices_0xfdad
      enable-take-address=false, indirect-api=false, port=DidServices_0xfdae
      enable-take-address=false, indirect-api=false, port=DidServices_0xfdaf
      enable-take-address=false, indirect-api=false, port=DidServices_0xfdb{0..7}
      enable-take-address=false, indirect-api=false, port=DidServices_0xfe00
      enable-take-address=false, indirect-api=false, port=ECUHardwareNumber
      enable-take-address=false, indirect-api=false, port=ECUSerialNumber
      enable-take-address=false, indirect-api=false, port=HaitecTrqCmd_SCom
      enable-take-address=false, indirect-api=false, port=LrnEOT_Scom
      enable-take-address=false, indirect-api=false, port=MEC
      enable-take-address=false, indirect-api=false, port=NxtrDiagMgr
      enable-take-address=false, indirect-api=false, port=RoutineServices_0xf000
      enable-take-address=false, indirect-api=false, port=RoutineServices_0xf001
      enable-take-address=false, indirect-api=false, port=RoutineServices_0xf{003..005}
      enable-take-address=false, indirect-api=false, port=RoutineServices_0xf008
      enable-take-address=false, indirect-api=false, port=RoutineServices_0xf009
      enable-take-address=false, indirect-api=false, port=RoutineServices_0xf0ff
      enable-take-address=false, indirect-api=false, port=RoutineServices_0xfee0
      enable-take-address=false, indirect-api=false, port=SecurityAccess_1
      enable-take-address=false, indirect-api=false, port=SessionControl
      enable-take-address=false, indirect-api=false, port=SparePartNumber
      enable-take-address=false, indirect-api=false, port=StaMd_SCom
      enable-take-address=false, indirect-api=false, port=SupplierIdentifier
      enable-take-address=false, indirect-api=false, port=SystemState
      enable-take-address=false, indirect-api=false, port=TuningSetSelect
      enable-take-address=false, indirect-api=false, port=VehDyn_SCom
    109 x runnable:
      DiagSvc_Init1
        data read access READ_MEC_Cnt_enum: data-element=MEC.Cnt_enum
        data write access WRITE_DesiredTunSet_Cnt_u16: data-element=DesiredTunSet.Cnt_u16
        sync call SC_NxtrDiagMgr_SetNTCStatus: operation=NxtrDiagMgr.SetNTCStatus, timeout=0
        sync call SC_TuningSetSelect_GetErrorStatus: operation=TuningSetSelect.GetErrorStatus, timeout=0
      DiagSvc_SCom_GetTuningSet
        sync call SC_TuningSetSelect_GetErrorStatus: operation=TuningSetSelect.GetErrorStatus, timeout=0
      DiagSvc_SCom_SetTuningSet
        data receive point REC_MEC_Cnt_enum: data-element=MEC.Cnt_enum
        sync call SC_NxtrDiagMgr_SetNTCStatus: operation=NxtrDiagMgr.SetNTCStatus, timeout=0
        sync call SC_TuningSetSelect_InvalidateNvBlock: operation=TuningSetSelect.InvalidateNvBlock, timeout=0
        sync call SC_TuningSetSelect_WriteBlock: operation=TuningSetSelect.WriteBlock, timeout=0
      DidServices_0x0100_ReadData
        sync call SC_TuningSetSelect_GetErrorStatus: operation=TuningSetSelect.GetErrorStatus, timeout=0
      DidServices_0x0100_WriteData
        data receive point REC_MEC_Cnt_enum: data-element=MEC.Cnt_enum
        sync call SC_NxtrDiagMgr_SetNTCStatus: operation=NxtrDiagMgr.SetNTCStatus, timeout=0
        sync call SC_TuningSetSelect_InvalidateNvBlock: operation=TuningSetSelect.InvalidateNvBlock, timeout=0
        sync call SC_TuningSetSelect_WriteBlock: operation=TuningSetSelect.WriteBlock, timeout=0
      DidServices_0xf180_ReadData
      DidServices_0xf187_ReadData
        sync call SC_SparePartNumber_GetErrorStatus: operation=SparePartNumber.GetErrorStatus, timeout=0
      DidServices_0xf187_WriteData
        sync call SC_SparePartNumber_WriteBlock: operation=SparePartNumber.WriteBlock, timeout=0
      DidServices_0xf18a_ReadData
        sync call SC_SupplierIdentifier_GetErrorStatus: operation=SupplierIdentifier.GetErrorStatus, timeout=0
      DidServices_0xf18a_WriteData
        sync call SC_SupplierIdentifier_WriteBlock: operation=SupplierIdentifier.WriteBlock, timeout=0
      DidServices_0xf18c_ReadData
        sync call SC_ECUSerialNumber_GetErrorStatus: operation=ECUSerialNumber.GetErrorStatus, timeout=0
      DidServices_0xf191_ReadData
        sync call SC_ECUHardwareNumber_GetErrorStatus: operation=ECUHardwareNumber.GetErrorStatus, timeout=0
      DidServices_0xf193_ReadData
        sync call SC_ECUHardwareNumber_GetErrorStatus: operation=ECUHardwareNumber.GetErrorStatus, timeout=0
      DidServices_0xf194_ReadData
      DidServices_0xf195_ReadData
      DidServices_0xfd01_ReadData
      DidServices_0xfd02_ReadData
      DidServices_0xfd02_WriteData
      DidServices_0xfd07_ReadData
      DidServices_0xfd07_WriteData
      DidServices_0xfd0d_ReadData
      DidServices_0xfd0d_ReturnControlToECU
      DidServices_0xfd0d_ShortTermAdjustment
      DidServices_0xfd0e_ReadData
      DidServices_0xfd10_ReadData
      DidServices_0xfd11_ReadData
      DidServices_0xfd11_ReturnControlToECU
      DidServices_0xfd11_ShortTermAdjustment
      DidServices_0xfd12_ReadData
      DidServices_0xfd12_WriteData
      DidServices_0xfd13_ReadData
      DidServices_0xfd14_ReadData
      DidServices_0xfd17_ReadData
      DidServices_0xfd19_ReadData
      DidServices_0xfd19_WriteData
      DidServices_0xfd1a_ReadData
      DidServices_0xfd1b_ReadData
      DidServices_0xfd1b_WriteData
      DidServices_0xfd1c_ReadData
      DidServices_0xfd1e_ReadData
      DidServices_0xfd1e_WriteData
      DidServices_0xfd20_ReadData
      DidServices_0xfd21_ReadData
      DidServices_0xfd21_WriteData
      DidServices_0xfd23_ReadData
      DidServices_0xfd23_WriteData
      DidServices_0xfd25_ReadData
      DidServices_0xfd25_WriteData
      DidServices_0xfd26_ReadData
      DidServices_0xfd26_WriteData
      DidServices_0xfd27_ReadData
      DidServices_0xfd27_WriteData
      DidServices_0xfd29_ReadData
      DidServices_0xfd29_WriteData
      DidServices_0xfd30_ReadData
      DidServices_0xfd30_WriteData
      DidServices_0xfd31_ReadData
      DidServices_0xfda1_ReadData
      DidServices_0xfda1_WriteData
      DidServices_0xfda2_ReadData
      DidServices_0xfda2_WriteData
      DidServices_0xfda3_ReadData
      DidServices_0xfda3_WriteData
      DidServices_0xfdac_ReadData
      DidServices_0xfdac_WriteData
      DidServices_0xfdad_ReadData
      DidServices_0xfdae_ReadData
      DidServices_0xfdae_WriteData
      DidServices_0xfdaf_ReadData
      DidServices_0xfdb0_ReadData
      DidServices_0xfdb0_WriteData
      DidServices_0xfdb1_ReadData
      DidServices_0xfdb1_WriteData
      DidServices_0xfdb2_ReadData
      DidServices_0xfdb2_WriteData
      DidServices_0xfdb3_ReadData
      DidServices_0xfdb3_WriteData
      DidServices_0xfdb4_ReadData
      DidServices_0xfdb4_WriteData
      DidServices_0xfdb5_ReadData
      DidServices_0xfdb5_WriteData
      DidServices_0xfdb6_ReadData
      DidServices_0xfdb6_WriteData
      DidServices_0xfdb7_ReadData
      DidServices_0xfdb7_WriteData
      DidServices_0xfe00_ReadData
      DidServices_0xfe00_ReturnControlToECU
        data receive point REC_MEC_Cnt_enum: data-element=MEC.Cnt_enum
        sync call SC_DCMServices_GetSesCtrlType: operation=DCMServices.GetSesCtrlType, timeout=0
        sync call SC_HaitecTrqCmd_SCom_StopCtrl: operation=HaitecTrqCmd_SCom.StopCtrl, timeout=0
      DidServices_0xfe00_ShortTermAdjustment
        data receive point REC_MEC_Cnt_enum: data-element=MEC.Cnt_enum
        sync call SC_DCMServices_GetSesCtrlType: operation=DCMServices.GetSesCtrlType, timeout=0
        sync call SC_HaitecTrqCmd_SCom_StartCtrl: operation=HaitecTrqCmd_SCom.StartCtrl, timeout=0
      DidServices_Customer_ConditionCheckRead
      DidServices_Customer_ConditionCheckWrite
      DidServices_Nexteer_ConditionCheckRead
        data receive point REC_MEC_Cnt_enum: data-element=MEC.Cnt_enum
        sync call SC_DCMServices_GetSesCtrlType: operation=DCMServices.GetSesCtrlType, timeout=0
      DidServices_Nexteer_ConditionCheckWrite
        data receive point REC_MEC_Cnt_enum: data-element=MEC.Cnt_enum
        sync call SC_DCMServices_GetSesCtrlType: operation=DCMServices.GetSesCtrlType, timeout=0
      DidServices_Service2F_ConditionCheckRead
      RoutineServices_0xf000_Start
      RoutineServices_0xf001_Start
      RoutineServices_0xf{003..005}_Start
      RoutineServices_0xf008_Start
      RoutineServices_0xf009_RequestResults
      RoutineServices_0xf009_Start
      RoutineServices_0xf009_Stop
      RoutineServices_0xf0ff_Start
      RoutineServices_0xfee0_Start
        4 x sync call, all with timeout=0:
          SC_AbsHwPos_SCom_CustClrTrim: operation=AbsHwPos_SCom.CustClrTrim
          SC_AbsHwPos_SCom_CustSetTrim: operation=AbsHwPos_SCom.CustSetTrim
          SC_LrnEOT_Scom_ResetEOT: operation=LrnEOT_Scom.ResetEOT
          SC_VehDyn_SCom_ResetCenter: operation=VehDyn_SCom.ResetCenter
      SecurityAccess_1_CompareKey
      SecurityAccess_1_GetSeed
        sync call SC_DCMServices_GetSecurityLevel: operation=DCMServices.GetSecurityLevel, timeout=0
      SessionControl_ChangeIndication
      SessionControl_ConfirmationRespPending
      SessionControl_GetSesChgPermission
    service-needss:
      swc nv block needs TuningSetSelect: n-data-sets=0, readonly=false, reliability=LOW, resistant-to-changed-sw=false, restore-at-start=false, write-only-once=false, writing-frequency=0, writing-priority=LOW, mirror-block=TuningSetSelectData
      swc nv block needs SupplierIdentifier: n-data-sets=0, readonly=false, reliability=LOW, resistant-to-changed-sw=false, restore-at-start=false, write-only-once=false, writing-frequency=0, writing-priority=LOW, mirror-block=SupplierIdentifierData
      swc nv block needs SparePartNumber: n-data-sets=0, readonly=false, reliability=LOW, resistant-to-changed-sw=false, restore-at-start=false, write-only-once=false, writing-frequency=0, writing-priority=LOW, mirror-block=SparePartNumberData
  swc implementation Ap_DiagSvc_Implementation: behavior=Ap_DiagSvc_InternalBehavior
    code-descriptors:
      code Code: type=SRC
